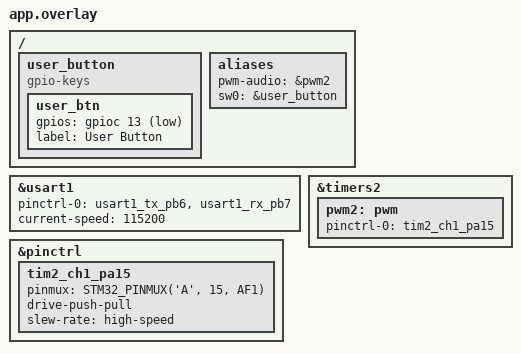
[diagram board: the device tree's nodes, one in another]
/*
 * Device tree overlay for MP3 Rewind Audio Streaming
 * STM32L475 Discovery Board - PWM Audio Output
 * 
 * Minimal overlay that enables PWM audio output and relies on board defaults
 * for WiFi (ISM43362) and Bluetooth LE (SPBTLE-RF) modules
 */

/ {
    /* User button configuration */
    user_button: user_button {
        compatible = "gpio-keys";
        user_btn: user_btn {
            gpios = <&gpioc 13 (GPIO_ACTIVE_LOW | GPIO_PULL_UP)>;
            label = "User Button";
        };
    };
    
    /* Aliases for our application */
    aliases {
        pwm-audio = &pwm2;
        sw0 = &user_button;
    };
};

/* Configure USART1 for logging (ST-LINK virtual COM port) */
&usart1 {
    status = "okay";
    pinctrl-0 = <&usart1_tx_pb6 &usart1_rx_pb7>;
    pinctrl-names = "default";
    current-speed = <115200>;
};

/* Enable PWM2 for audio output */
&timers2 {
	status = "okay";

	pwm2: pwm {
		status = "okay";
		pinctrl-0 = <&tim2_ch1_pa15>;
		pinctrl-names = "default";
	};
};

/* Enable PWM pinctrl */
&pinctrl {
    /* PWM2 channel 1 on PA15 for audio output (Arduino D9) */
    tim2_ch1_pa15: tim2_ch1_pa15 {
        pinmux = <STM32_PINMUX('A', 15, AF1)>;
        drive-push-pull;
        slew-rate = "high-speed";
    };
};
